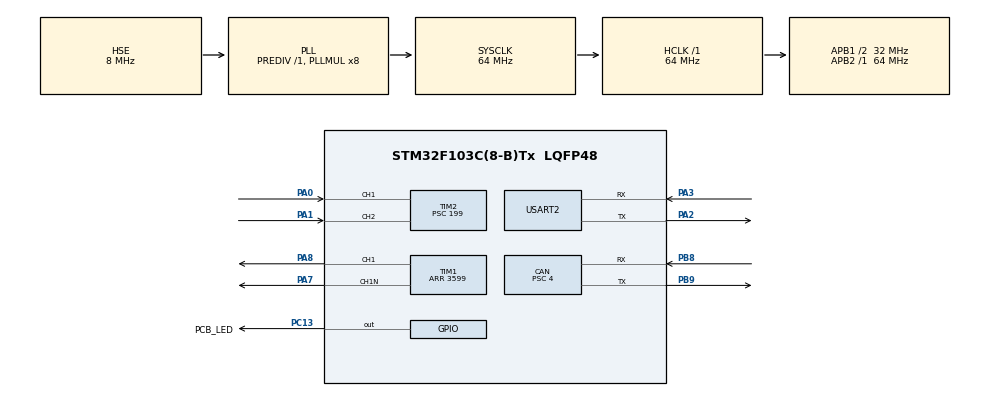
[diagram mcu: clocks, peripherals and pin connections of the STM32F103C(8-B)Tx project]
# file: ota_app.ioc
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CAN.ABOM=ENABLE
CAN.BS1=CAN_BS1_14TQ
CAN.CalculateBaudRate=500000
CAN.CalculateTimeBit=2000
CAN.CalculateTimeQuantum=125.0
CAN.Prescaler=4
Mcu.Family=STM32F1
Mcu.Name=STM32F103C(8-B)Tx
Mcu.Package=LQFP48
NVIC.PriorityGroup=NVIC_PRIORITYGROUP_4
NVIC.TIM2_IRQn=true\:0\:0\:false\:false\:true\:true\:true\:true
NVIC.USART2_IRQn=true\:0\:0\:false\:false\:true\:true\:true\:true
NVIC.USB_LP_CAN1_RX0_IRQn=true\:0\:0\:false\:false\:true\:true\:true\:true
PA0-WKUP.Signal=S_TIM2_CH1_ETR
PA1.Signal=S_TIM2_CH2
PA13.Mode=Serial_Wire
PA13.Signal=SYS_JTMS-SWDIO
PA14.Mode=Serial_Wire
PA14.Signal=SYS_JTCK-SWCLK
PA2.Mode=Asynchronous
PA2.Signal=USART2_TX
PA3.Mode=Asynchronous
PA3.Signal=USART2_RX
PA7.Mode=PWM Generation1 CH1 CH1N
PA7.Signal=TIM1_CH1N
PA8.Signal=S_TIM1_CH1
PB8.Mode=CAN_Activate
PB8.Signal=CAN_RX
PB9.Mode=CAN_Activate
PB9.Signal=CAN_TX
PC13-TAMPER-RTC.GPIO_Label=PCB_LED
PC13-TAMPER-RTC.Signal=GPIO_Output
PD0-OSC_IN.Mode=HSE-External-Oscillator
PD0-OSC_IN.Signal=RCC_OSC_IN
PD1-OSC_OUT.Mode=HSE-External-Oscillator
PD1-OSC_OUT.Signal=RCC_OSC_OUT
ProjectManager.HeapSize=0x200
ProjectManager.StackSize=0x400
ProjectManager.TargetToolchain=STM32CubeIDE
RCC.AHBFreq_Value=64000000
RCC.APB1CLKDivider=RCC_HCLK_DIV2
RCC.APB1Freq_Value=32000000
RCC.APB1TimFreq_Value=64000000
RCC.APB2Freq_Value=64000000
RCC.APB2TimFreq_Value=64000000
RCC.HCLKFreq_Value=64000000
RCC.PLLMUL=RCC_PLL_MUL8
RCC.PLLSourceVirtual=RCC_PLLSOURCE_HSE
RCC.SYSCLKFreq_VALUE=64000000
RCC.SYSCLKSource=RCC_SYSCLKSOURCE_PLLCLK
RCC.USBFreq_Value=64000000
SH.S_TIM1_CH1.0=TIM1_CH1,PWM Generation1 CH1 CH1N
SH.S_TIM2_CH1_ETR.0=TIM2_CH1,Input_Capture1_from_TI1
SH.S_TIM2_CH2.0=TIM2_CH2,Input_Capture2_from_TI2
TIM1.AutoReloadPreload=TIM_AUTORELOAD_PRELOAD_ENABLE
TIM1.AutomaticOutput=TIM_AUTOMATICOUTPUT_ENABLE
TIM1.Channel-PWM\ Generation1\ CH1\ CH1N=TIM_CHANNEL_1
TIM1.CounterMode=TIM_COUNTERMODE_UP
TIM1.DeadTime=36
TIM1.OffStateIDLEMode=TIM_OSSI_ENABLE
TIM1.OffStateRunMode=TIM_OSSR_ENABLE
TIM1.Period=3599
TIM2.Channel-Input_Capture1_from_TI1=TIM_CHANNEL_1
TIM2.Channel-Input_Capture2_from_TI2=TIM_CHANNEL_2
TIM2.ICFilter_CH1=15
TIM2.ICFilter_CH2=15
TIM2.Prescaler=199
USART2.VirtualMode=VM_ASYNC
VP_TIM1_VS_ClockSourceINT.Mode=Internal
VP_TIM2_VS_ClockSourceINT.Mode=Internal
VP_TIM2_VS_XOR.Mode=XOR_enable
board=custom

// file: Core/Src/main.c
/* USER CODE BEGIN Header */
/**
  ******************************************************************************
  * @file           : main.c
  * @brief          : Main program body
  ******************************************************************************
  * @attention
  *
  * Copyright (c) 2024 STMicroelectronics.
  * All rights reserved.
  *
  * This software is licensed under terms that can be found in the LICENSE file
  * in the root directory of this software component.
  * If no LICENSE file comes with this software, it is provided AS-IS.
  *
  ******************************************************************************
  */
/* USER CODE END Header */
#include "main.h"

/* USER CODE BEGIN Includes */
#include "mcal/com/com_proc.h"
#include "dcm/dcm.h"
/* USER CODE END Includes */

CAN_HandleTypeDef hcan;

TIM_HandleTypeDef htim1;
TIM_HandleTypeDef htim2;

UART_HandleTypeDef huart2;

void SystemClock_Config(void);
static void MX_GPIO_Init(void);
static void MX_CAN_Init(void);
static void MX_TIM1_Init(void);
static void MX_TIM2_Init(void);
static void MX_USART2_UART_Init(void);

int main(void)
{

  /* MCU Configuration--------------------------------------------------------*/

  /* Reset of all peripherals, Initializes the Flash interface and the Systick. */
  HAL_Init();

  /* Configure the system clock */
  SystemClock_Config();

  /* Initialize all configured peripherals */
  MX_GPIO_Init();
  MX_CAN_Init();
  MX_TIM1_Init();
  MX_TIM2_Init();
  MX_USART2_UART_Init();
  /* USER CODE BEGIN 2 */
  COM_Proc_Init();
  DCM_Proc_Init();

  // float set_speed;
  // float act_speed;
  // dc_ctrl_init(&set_speed, &act_speed);

  /* USER CODE END 2 */

  /* Infinite loop */
  /* USER CODE BEGIN WHILE */
  while (1)
  {
	  COM_Proc_1ms();
	  HAL_Delay(1);

	  static uint16_t counter = 0;
	  if ((counter++ % 100) == 0)
		{
		  HAL_UART_Transmit(&huart2, "App running 222\r\n", sizeof("App running 222\r\n"), 1000);
		  HAL_GPIO_TogglePin(GPIOC, GPIO_PIN_13);
		}

    /* USER CODE END WHILE */

  }
}

void SystemClock_Config(void)
{
  RCC_OscInitTypeDef RCC_OscInitStruct = {0};
  RCC_ClkInitTypeDef RCC_ClkInitStruct = {0};

  /** Initializes the RCC Oscillators according to the specified parameters
  * in the RCC_OscInitTypeDef structure.
  */
  RCC_OscInitStruct.OscillatorType = RCC_OSCILLATORTYPE_HSE;
  RCC_OscInitStruct.HSEState = RCC_HSE_ON;
  RCC_OscInitStruct.HSEPredivValue = RCC_HSE_PREDIV_DIV1;
  RCC_OscInitStruct.HSIState = RCC_HSI_ON;
  RCC_OscInitStruct.PLL.PLLState = RCC_PLL_ON;
  RCC_OscInitStruct.PLL.PLLSource = RCC_PLLSOURCE_HSE;
  RCC_OscInitStruct.PLL.PLLMUL = RCC_PLL_MUL8;
  if (HAL_RCC_OscConfig(&RCC_OscInitStruct) != HAL_OK)
  {
    Error_Handler();
  }

  /** Initializes the CPU, AHB and APB buses clocks
  */
  RCC_ClkInitStruct.ClockType = RCC_CLOCKTYPE_HCLK|RCC_CLOCKTYPE_SYSCLK
                              |RCC_CLOCKTYPE_PCLK1|RCC_CLOCKTYPE_PCLK2;
  RCC_ClkInitStruct.SYSCLKSource = RCC_SYSCLKSOURCE_PLLCLK;
  RCC_ClkInitStruct.AHBCLKDivider = RCC_SYSCLK_DIV1;
  RCC_ClkInitStruct.APB1CLKDivider = RCC_HCLK_DIV2;
  RCC_ClkInitStruct.APB2CLKDivider = RCC_HCLK_DIV1;

  if (HAL_RCC_ClockConfig(&RCC_ClkInitStruct, FLASH_LATENCY_2) != HAL_OK)
  {
    Error_Handler();
  }
}

static void MX_CAN_Init(void)
{

  hcan.Instance = CAN1;
  hcan.Init.Prescaler = 4;
  hcan.Init.Mode = CAN_MODE_NORMAL;
  hcan.Init.SyncJumpWidth = CAN_SJW_1TQ;
  hcan.Init.TimeSeg1 = CAN_BS1_14TQ;
  hcan.Init.TimeSeg2 = CAN_BS2_1TQ;
  hcan.Init.TimeTriggeredMode = DISABLE;
  hcan.Init.AutoBusOff = ENABLE;
  hcan.Init.AutoWakeUp = DISABLE;
  hcan.Init.AutoRetransmission = DISABLE;
  hcan.Init.ReceiveFifoLocked = DISABLE;
  hcan.Init.TransmitFifoPriority = DISABLE;
  if (HAL_CAN_Init(&hcan) != HAL_OK)
  {
    Error_Handler();
  }

}

static void MX_TIM1_Init(void)
{

  /* USER CODE BEGIN TIM1_Init 0 */
//
  /* USER CODE END TIM1_Init 0 */

  TIM_ClockConfigTypeDef sClockSourceConfig = {0};
  TIM_MasterConfigTypeDef sMasterConfig = {0};
  TIM_OC_InitTypeDef sConfigOC = {0};
  TIM_BreakDeadTimeConfigTypeDef sBreakDeadTimeConfig = {0};

  /* USER CODE BEGIN TIM1_Init 1 */
//
  /* USER CODE END TIM1_Init 1 */
  htim1.Instance = TIM1;
  htim1.Init.Prescaler = 0;
  htim1.Init.CounterMode = TIM_COUNTERMODE_UP;
  htim1.Init.Period = 3599;
  htim1.Init.ClockDivision = TIM_CLOCKDIVISION_DIV1;
  htim1.Init.RepetitionCounter = 0;
  htim1.Init.AutoReloadPreload = TIM_AUTORELOAD_PRELOAD_ENABLE;
  if (HAL_TIM_Base_Init(&htim1) != HAL_OK)
  {
    Error_Handler();
  }
  sClockSourceConfig.ClockSource = TIM_CLOCKSOURCE_INTERNAL;
  if (HAL_TIM_ConfigClockSource(&htim1, &sClockSourceConfig) != HAL_OK)
  {
    Error_Handler();
  }
  if (HAL_TIM_PWM_Init(&htim1) != HAL_OK)
  {
    Error_Handler();
  }
  sMasterConfig.MasterOutputTrigger = TIM_TRGO_RESET;
  sMasterConfig.MasterSlaveMode = TIM_MASTERSLAVEMODE_DISABLE;
  if (HAL_TIMEx_MasterConfigSynchronization(&htim1, &sMasterConfig) != HAL_OK)
  {
    Error_Handler();
  }
  sConfigOC.OCMode = TIM_OCMODE_PWM1;
  sConfigOC.Pulse = 0;
  sConfigOC.OCPolarity = TIM_OCPOLARITY_HIGH;
  sConfigOC.OCNPolarity = TIM_OCNPOLARITY_HIGH;
  sConfigOC.OCFastMode = TIM_OCFAST_DISABLE;
  sConfigOC.OCIdleState = TIM_OCIDLESTATE_RESET;
  sConfigOC.OCNIdleState = TIM_OCNIDLESTATE_RESET;
  if (HAL_TIM_PWM_ConfigChannel(&htim1, &sConfigOC, TIM_CHANNEL_1) != HAL_OK)
  {
    Error_Handler();
  }
  sBreakDeadTimeConfig.OffStateRunMode = TIM_OSSR_ENABLE;
  sBreakDeadTimeConfig.OffStateIDLEMode = TIM_OSSI_ENABLE;
  sBreakDeadTimeConfig.LockLevel = TIM_LOCKLEVEL_OFF;
  sBreakDeadTimeConfig.DeadTime = 36;
  sBreakDeadTimeConfig.BreakState = TIM_BREAK_DISABLE;
  sBreakDeadTimeConfig.BreakPolarity = TIM_BREAKPOLARITY_HIGH;
  sBreakDeadTimeConfig.AutomaticOutput = TIM_AUTOMATICOUTPUT_ENABLE;
  if (HAL_TIMEx_ConfigBreakDeadTime(&htim1, &sBreakDeadTimeConfig) != HAL_OK)
  {
    Error_Handler();
  }
  /* USER CODE BEGIN TIM1_Init 2 */
//
  /* USER CODE END TIM1_Init 2 */
  HAL_TIM_MspPostInit(&htim1);

}

static void MX_TIM2_Init(void)
{

  /* USER CODE BEGIN TIM2_Init 0 */
//
  /* USER CODE END TIM2_Init 0 */

  TIM_ClockConfigTypeDef sClockSourceConfig = {0};
  TIM_MasterConfigTypeDef sMasterConfig = {0};
  TIM_IC_InitTypeDef sConfigIC = {0};

  /* USER CODE BEGIN TIM2_Init 1 */
//
  /* USER CODE END TIM2_Init 1 */
  htim2.Instance = TIM2;
  htim2.Init.Prescaler = 199;
  htim2.Init.CounterMode = TIM_COUNTERMODE_UP;
  htim2.Init.Period = 65535;
  htim2.Init.ClockDivision = TIM_CLOCKDIVISION_DIV1;
  htim2.Init.AutoReloadPreload = TIM_AUTORELOAD_PRELOAD_DISABLE;
  if (HAL_TIM_Base_Init(&htim2) != HAL_OK)
  {
    Error_Handler();
  }
  sClockSourceConfig.ClockSource = TIM_CLOCKSOURCE_INTERNAL;
  if (HAL_TIM_ConfigClockSource(&htim2, &sClockSourceConfig) != HAL_OK)
  {
    Error_Handler();
  }
  if (HAL_TIM_IC_Init(&htim2) != HAL_OK)
  {
    Error_Handler();
  }
  sMasterConfig.MasterOutputTrigger = TIM_TRGO_RESET;
  sMasterConfig.MasterSlaveMode = TIM_MASTERSLAVEMODE_DISABLE;
  if (HAL_TIMEx_MasterConfigSynchronization(&htim2, &sMasterConfig) != HAL_OK)
  {
    Error_Handler();
  }
  sConfigIC.ICPolarity = TIM_INPUTCHANNELPOLARITY_RISING;
  sConfigIC.ICSelection = TIM_ICSELECTION_DIRECTTI;
  sConfigIC.ICPrescaler = TIM_ICPSC_DIV1;
  sConfigIC.ICFilter = 15;
  if (HAL_TIM_IC_ConfigChannel(&htim2, &sConfigIC, TIM_CHANNEL_1) != HAL_OK)
  {
    Error_Handler();
  }
  if (HAL_TIM_IC_ConfigChannel(&htim2, &sConfigIC, TIM_CHANNEL_2) != HAL_OK)
  {
    Error_Handler();
  }
  if (HAL_TIM_ConfigTI1Input(&htim2, TIM_TI1SELECTION_XORCOMBINATION) != HAL_OK)
  {
    Error_Handler();
  }
  /* USER CODE BEGIN TIM2_Init 2 */
//
  /* USER CODE END TIM2_Init 2 */

}

static void MX_USART2_UART_Init(void)
{

  huart2.Instance = USART2;
  huart2.Init.BaudRate = 115200;
  huart2.Init.WordLength = UART_WORDLENGTH_8B;
  huart2.Init.StopBits = UART_STOPBITS_1;
  huart2.Init.Parity = UART_PARITY_NONE;
  huart2.Init.Mode = UART_MODE_TX_RX;
  huart2.Init.HwFlowCtl = UART_HWCONTROL_NONE;
  huart2.Init.OverSampling = UART_OVERSAMPLING_16;
  if (HAL_UART_Init(&huart2) != HAL_OK)
  {
    Error_Handler();
  }

}

static void MX_GPIO_Init(void)
{
  GPIO_InitTypeDef GPIO_InitStruct = {0};

  /* GPIO Ports Clock Enable */
  __HAL_RCC_GPIOC_CLK_ENABLE();
  __HAL_RCC_GPIOD_CLK_ENABLE();
  __HAL_RCC_GPIOA_CLK_ENABLE();
  __HAL_RCC_GPIOB_CLK_ENABLE();

  /*Configure GPIO pin Output Level */
  HAL_GPIO_WritePin(PCB_LED_GPIO_Port, PCB_LED_Pin, GPIO_PIN_RESET);

  /*Configure GPIO pin : PCB_LED_Pin */
  GPIO_InitStruct.Pin = PCB_LED_Pin;
  GPIO_InitStruct.Mode = GPIO_MODE_OUTPUT_PP;
  GPIO_InitStruct.Pull = GPIO_NOPULL;
  GPIO_InitStruct.Speed = GPIO_SPEED_FREQ_LOW;
  HAL_GPIO_Init(PCB_LED_GPIO_Port, &GPIO_InitStruct);

}

void Error_Handler(void)
{
  __disable_irq();
  while (1)
  {
  }
}
